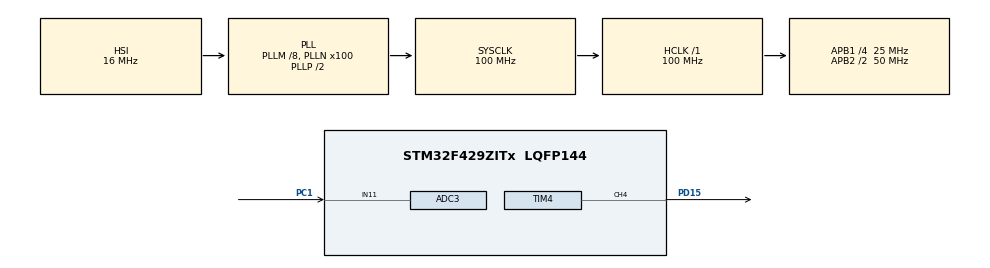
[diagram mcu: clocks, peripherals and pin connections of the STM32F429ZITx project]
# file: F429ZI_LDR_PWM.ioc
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ADC3.Channel-4\#ChannelRegularConversion=ADC_CHANNEL_11
ADC3.NbrOfConversionFlag=1
ADC3.Rank-4\#ChannelRegularConversion=1
ADC3.SamplingTime-4\#ChannelRegularConversion=ADC_SAMPLETIME_3CYCLES
Mcu.Family=STM32F4
Mcu.Name=STM32F429ZITx
Mcu.Package=LQFP144
NVIC.PriorityGroup=NVIC_PRIORITYGROUP_0
PC1.Signal=ADCx_IN11
PD15.Signal=S_TIM4_CH4
ProjectManager.HeapSize=0x200
ProjectManager.StackSize=0x400
ProjectManager.TargetToolchain=STM32CubeIDE
RCC.48MHZClocksFreq_Value=28571428.57142857
RCC.AHBFreq_Value=100000000
RCC.APB1CLKDivider=RCC_HCLK_DIV4
RCC.APB1Freq_Value=25000000
RCC.APB1TimFreq_Value=50000000
RCC.APB2CLKDivider=RCC_HCLK_DIV2
RCC.APB2Freq_Value=50000000
RCC.APB2TimFreq_Value=100000000
RCC.CortexFreq_Value=100000000
RCC.HCLKFreq_Value=100000000
RCC.HSE_VALUE=8000000
RCC.HSI_VALUE=16000000
RCC.LSE_VALUE=32768
RCC.PLLM=8
RCC.PLLN=100
RCC.PLLQ=7
RCC.SYSCLKFreq_VALUE=100000000
RCC.SYSCLKSource=RCC_SYSCLKSOURCE_PLLCLK
RCC.VCOOutputFreq_Value=200000000
SH.ADCx_IN11.0=ADC3_IN11,IN11
SH.S_TIM4_CH4.0=TIM4_CH4,PWM Generation4 CH4
TIM4.Channel-PWM\ Generation4\ CH4=TIM_CHANNEL_4
TIM4.Period=999
TIM4.Prescaler=50
board=STM32F429I-DISC1

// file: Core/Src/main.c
/* USER CODE BEGIN Header */
/**
  ******************************************************************************
  * @file           : main.c
  * @brief          : Main program body
  ******************************************************************************
  * @attention
  *
  * Copyright (c) 2023 STMicroelectronics.
  * All rights reserved.
  *
  * This software is licensed under terms that can be found in the LICENSE file
  * in the root directory of this software component.
  * If no LICENSE file comes with this software, it is provided AS-IS.
  *
  ******************************************************************************
  */
/* USER CODE END Header */
#include "main.h"

ADC_HandleTypeDef hadc3;

TIM_HandleTypeDef htim4;

void SystemClock_Config(void);
static void MX_GPIO_Init(void);
static void MX_ADC3_Init(void);
static void MX_TIM4_Init(void);

/* USER CODE BEGIN 0 */
uint32_t x = 0;
uint16_t adc;
/* USER CODE END 0 */

int main(void)
{

  /* MCU Configuration--------------------------------------------------------*/

  /* Reset of all peripherals, Initializes the Flash interface and the Systick. */
  HAL_Init();

  /* Configure the system clock */
  SystemClock_Config();

  /* Initialize all configured peripherals */
  MX_GPIO_Init();
  MX_ADC3_Init();
  MX_TIM4_Init();
  /* USER CODE BEGIN 2 */
  HAL_TIM_PWM_Start(&htim4, TIM_CHANNEL_4);
  /* USER CODE END 2 */

  /* Infinite loop */
  while (1)
  {

    /* USER CODE BEGIN 3 */
	HAL_ADC_Start(&hadc3);
	HAL_ADC_PollForConversion(&hadc3, 10);
	adc = HAL_ADC_GetValue(&hadc3);
	x = ((float)adc/4095.0f) * 999.0f;
	TIM4->CCR4 = x;

  }
  /* USER CODE END 3 */
}

void SystemClock_Config(void)
{
  RCC_OscInitTypeDef RCC_OscInitStruct = {0};
  RCC_ClkInitTypeDef RCC_ClkInitStruct = {0};

  /** Configure the main internal regulator output voltage
  */
  __HAL_RCC_PWR_CLK_ENABLE();
  __HAL_PWR_VOLTAGESCALING_CONFIG(PWR_REGULATOR_VOLTAGE_SCALE3);

  /** Initializes the RCC Oscillators according to the specified parameters
  * in the RCC_OscInitTypeDef structure.
  */
  RCC_OscInitStruct.OscillatorType = RCC_OSCILLATORTYPE_HSI;
  RCC_OscInitStruct.HSIState = RCC_HSI_ON;
  RCC_OscInitStruct.HSICalibrationValue = RCC_HSICALIBRATION_DEFAULT;
  RCC_OscInitStruct.PLL.PLLState = RCC_PLL_ON;
  RCC_OscInitStruct.PLL.PLLSource = RCC_PLLSOURCE_HSI;
  RCC_OscInitStruct.PLL.PLLM = 8;
  RCC_OscInitStruct.PLL.PLLN = 100;
  RCC_OscInitStruct.PLL.PLLP = RCC_PLLP_DIV2;
  RCC_OscInitStruct.PLL.PLLQ = 7;
  if (HAL_RCC_OscConfig(&RCC_OscInitStruct) != HAL_OK)
  {
    Error_Handler();
  }

  /** Initializes the CPU, AHB and APB buses clocks
  */
  RCC_ClkInitStruct.ClockType = RCC_CLOCKTYPE_HCLK|RCC_CLOCKTYPE_SYSCLK
                              |RCC_CLOCKTYPE_PCLK1|RCC_CLOCKTYPE_PCLK2;
  RCC_ClkInitStruct.SYSCLKSource = RCC_SYSCLKSOURCE_PLLCLK;
  RCC_ClkInitStruct.AHBCLKDivider = RCC_SYSCLK_DIV1;
  RCC_ClkInitStruct.APB1CLKDivider = RCC_HCLK_DIV4;
  RCC_ClkInitStruct.APB2CLKDivider = RCC_HCLK_DIV2;

  if (HAL_RCC_ClockConfig(&RCC_ClkInitStruct, FLASH_LATENCY_3) != HAL_OK)
  {
    Error_Handler();
  }
}

static void MX_ADC3_Init(void)
{

  ADC_ChannelConfTypeDef sConfig = {0};

  /** Configure the global features of the ADC (Clock, Resolution, Data Alignment and number of conversion)
  */
  hadc3.Instance = ADC3;
  hadc3.Init.ClockPrescaler = ADC_CLOCK_SYNC_PCLK_DIV2;
  hadc3.Init.Resolution = ADC_RESOLUTION_12B;
  hadc3.Init.ScanConvMode = DISABLE;
  hadc3.Init.ContinuousConvMode = DISABLE;
  hadc3.Init.DiscontinuousConvMode = DISABLE;
  hadc3.Init.ExternalTrigConvEdge = ADC_EXTERNALTRIGCONVEDGE_NONE;
  hadc3.Init.ExternalTrigConv = ADC_SOFTWARE_START;
  hadc3.Init.DataAlign = ADC_DATAALIGN_RIGHT;
  hadc3.Init.NbrOfConversion = 1;
  hadc3.Init.DMAContinuousRequests = DISABLE;
  hadc3.Init.EOCSelection = ADC_EOC_SINGLE_CONV;
  if (HAL_ADC_Init(&hadc3) != HAL_OK)
  {
    Error_Handler();
  }

  /** Configure for the selected ADC regular channel its corresponding rank in the sequencer and its sample time.
  */
  sConfig.Channel = ADC_CHANNEL_11;
  sConfig.Rank = 1;
  sConfig.SamplingTime = ADC_SAMPLETIME_3CYCLES;
  if (HAL_ADC_ConfigChannel(&hadc3, &sConfig) != HAL_OK)
  {
    Error_Handler();
  }

}

static void MX_TIM4_Init(void)
{

  TIM_MasterConfigTypeDef sMasterConfig = {0};
  TIM_OC_InitTypeDef sConfigOC = {0};

  htim4.Instance = TIM4;
  htim4.Init.Prescaler = 50;
  htim4.Init.CounterMode = TIM_COUNTERMODE_UP;
  htim4.Init.Period = 999;
  htim4.Init.ClockDivision = TIM_CLOCKDIVISION_DIV1;
  htim4.Init.AutoReloadPreload = TIM_AUTORELOAD_PRELOAD_DISABLE;
  if (HAL_TIM_PWM_Init(&htim4) != HAL_OK)
  {
    Error_Handler();
  }
  sMasterConfig.MasterOutputTrigger = TIM_TRGO_RESET;
  sMasterConfig.MasterSlaveMode = TIM_MASTERSLAVEMODE_DISABLE;
  if (HAL_TIMEx_MasterConfigSynchronization(&htim4, &sMasterConfig) != HAL_OK)
  {
    Error_Handler();
  }
  sConfigOC.OCMode = TIM_OCMODE_PWM1;
  sConfigOC.Pulse = 0;
  sConfigOC.OCPolarity = TIM_OCPOLARITY_HIGH;
  sConfigOC.OCFastMode = TIM_OCFAST_DISABLE;
  if (HAL_TIM_PWM_ConfigChannel(&htim4, &sConfigOC, TIM_CHANNEL_4) != HAL_OK)
  {
    Error_Handler();
  }
  HAL_TIM_MspPostInit(&htim4);

}

static void MX_GPIO_Init(void)
{

  /* GPIO Ports Clock Enable */
  __HAL_RCC_GPIOC_CLK_ENABLE();
  __HAL_RCC_GPIOD_CLK_ENABLE();

}

void Error_Handler(void)
{
  __disable_irq();
  while (1)
  {
  }
}
